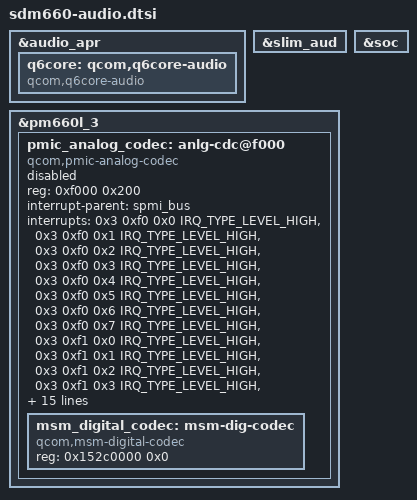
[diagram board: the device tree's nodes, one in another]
#include "sdm660-wsa881x.dtsi"

&audio_apr {
	q6core: qcom,q6core-audio {
		compatible = "qcom,q6core-audio";
	};
};


#include "sdm660-lpi.dtsi"

&q6core {
};

&q6core {

};

&slim_aud {
};

&pm660l_3 {
	pmic_analog_codec: anlg-cdc@f000 {
		status = "disabled";
		compatible = "qcom,pmic-analog-codec";
		reg = <0xf000 0x200>;
		#address-cells = <2>;
		#size-cells = <0>;
		interrupt-parent = <&spmi_bus>;
		interrupts = <0x3 0xf0 0x0 IRQ_TYPE_LEVEL_HIGH>,
				<0x3 0xf0 0x1 IRQ_TYPE_LEVEL_HIGH>,
				<0x3 0xf0 0x2 IRQ_TYPE_LEVEL_HIGH>,
				<0x3 0xf0 0x3 IRQ_TYPE_LEVEL_HIGH>,
				<0x3 0xf0 0x4 IRQ_TYPE_LEVEL_HIGH>,
				<0x3 0xf0 0x5 IRQ_TYPE_LEVEL_HIGH>,
				<0x3 0xf0 0x6 IRQ_TYPE_LEVEL_HIGH>,
				<0x3 0xf0 0x7 IRQ_TYPE_LEVEL_HIGH>,
				<0x3 0xf1 0x0 IRQ_TYPE_LEVEL_HIGH>,
				<0x3 0xf1 0x1 IRQ_TYPE_LEVEL_HIGH>,
				<0x3 0xf1 0x2 IRQ_TYPE_LEVEL_HIGH>,
				<0x3 0xf1 0x3 IRQ_TYPE_LEVEL_HIGH>,
				<0x3 0xf1 0x4 IRQ_TYPE_LEVEL_HIGH>,
				<0x3 0xf1 0x5 IRQ_TYPE_LEVEL_HIGH>;
		interrupt-names = "spk_cnp_int",
				  "spk_clip_int",
				  "spk_ocp_int",
				  "ins_rem_det1",
				  "but_rel_det",
				  "but_press_det",
				  "ins_rem_det",
				  "mbhc_int",
				  "ear_ocp_int",
				  "hphr_ocp_int",
				  "hphl_ocp_det",
				  "ear_cnp_int",
				  "hphr_cnp_int",
				  "hphl_cnp_int";


		cdc-vdda-cp-supply = <&pm660_s4>;
		qcom,cdc-vdda-cp-voltage = <1900000 2050000>;
		qcom,cdc-vdda-cp-current = <50000>;

		cdc-vdd-pa-supply = <&pm660_s4>;
		qcom,cdc-vdd-pa-voltage = <2040000 2040000>;
		qcom,cdc-vdd-pa-current = <260000>;

		cdc-vdd-mic-bias-supply = <&pm660l_l7>;
		qcom,cdc-vdd-mic-bias-voltage = <3088000 3088000>;
		qcom,cdc-vdd-mic-bias-current = <5000>;

		qcom,cdc-mclk-clk-rate = <9600000>;

		qcom,cdc-static-supplies = "cdc-vdda-cp",
					   "cdc-vdd-pa";

		qcom,cdc-on-demand-supplies = "cdc-vdd-mic-bias";

		/*
		 * Not marking address @ as driver searches this child
		 * with name msm-dig-codec
		 */
		msm_digital_codec: msm-dig-codec {
			compatible = "qcom,msm-digital-codec";
			reg = <0x152c0000 0x0>;
		};
	};
};

&soc {
};
